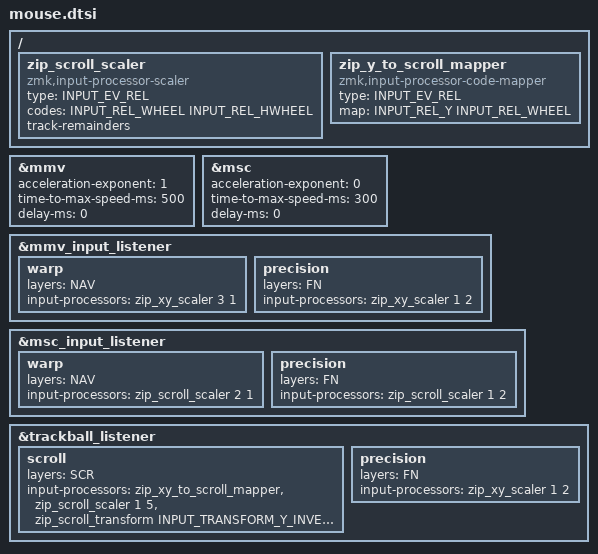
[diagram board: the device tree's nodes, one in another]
// Settings tuned for 3840 x 2160 display resolution
#define ZMK_POINTING_DEFAULT_MOVE_VAL 600 // 600
#define ZMK_POINTING_DEFAULT_SCRL_VAL 7  // 10

#include <dt-bindings/zmk/pointing.h>
#include <input/processors.dtsi>
#include <zephyr/dt-bindings/input/input-event-codes.h>
#include <dt-bindings/zmk/input_transform.h>

// Based on @caksoylar's config, defaults in comments
&mmv {
  acceleration-exponent = <1>;          // 1
  time-to-max-speed-ms = <500>;         // 300
  delay-ms = <0>;                       // 0
};

&msc {
  acceleration-exponent = <0>;          // 0
  time-to-max-speed-ms = <300>;         // 300
  delay-ms = <0>;                       // 0
};

&mmv_input_listener {
  warp {
    layers = <NAV>;
    input-processors = <&zip_xy_scaler 3 1>;
  };
  precision {
    layers = <FN>;
    input-processors = <&zip_xy_scaler 1 2>;
  };
};

/ {
  zip_scroll_scaler: zip_scroll_scaler {
    compatible = "zmk,input-processor-scaler";
    #input-processor-cells = <2>;
    type = <INPUT_EV_REL>;
    codes = <INPUT_REL_WHEEL INPUT_REL_HWHEEL>;
    track-remainders;
  };

  zip_y_to_scroll_mapper: zip_y_to_scroll_mapper {
    compatible = "zmk,input-processor-code-mapper";
    #input-processor-cells = <0>;
    type = <INPUT_EV_REL>;
    map = <INPUT_REL_Y INPUT_REL_WHEEL>;
  };

  // /omit-if-no-ref/ zip_temp_layer: zip_temp_layer {
  //     compatible = "zmk,input-processor-temp-layer";
  //     #input-processor-cells = <2>;
  //     require-prior-idle-ms = <180>;
  //     excluded-positions = <25 26 27 28 29>;
  // };
};

&msc_input_listener {
  warp {
    layers = <NAV>;
    input-processors = <&zip_scroll_scaler 2 1>;
  };
  precision {
    layers = <FN>;
    input-processors = <&zip_scroll_scaler 1 2>;
  };
};

&trackball_listener {
  // input-processors = <&zip_temp_layer 5 1000>;

  scroll {
    layers = <SCR>;
    input-processors = <&zip_xy_to_scroll_mapper>, <&zip_scroll_scaler 1 5>, <&zip_scroll_transform INPUT_TRANSFORM_Y_INVERT>;
  };

  precision {
    layers = <FN>;
    input-processors = <&zip_xy_scaler 1 2>;
  };
};

#define U_MS_U &mmv MOVE_UP
#define U_MS_D &mmv MOVE_DOWN
#define U_MS_L &mmv MOVE_LEFT
#define U_MS_R &mmv MOVE_RIGHT
#define U_WH_U &msc SCRL_UP
#define U_WH_D &msc SCRL_DOWN
#define U_WH_L &msc SCRL_LEFT
#define U_WH_R &msc SCRL_RIGHT
